# GD32H7xx register map
File version: 1.0
CPU: CM7 r1p2, little endian, MPU, FPU, 4 interrupt priority bits
Registers are 32-bit, read-write, reset 0x0 unless marked. A register's access mark holds for its fields unless they carry their own. Offsets are from the block's base; [hi:lo] are bit positions; {n}, {i} and the like mark numbered series.

## TRNG — True random number generator
Base 0x48021800
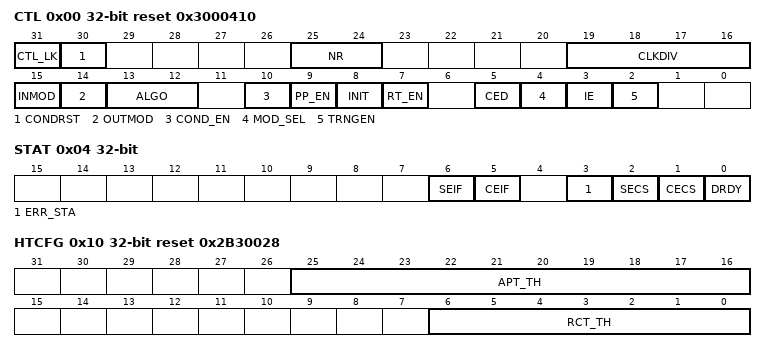
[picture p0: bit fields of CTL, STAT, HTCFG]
0x00 CTL access per field reset 0x3000410 — Control register
  [31] CTL_LK ro — TRNG_CTL register lock bit
  [30] CONDRST rw — reset conditioning logic
  [25:24] NR rw — analog trng power mode
  [19:16] CLKDIV rw — TRNG clock divider
  [15] INMOD rw — select random seed number input to conditioning module
  [14] OUTMOD rw — select random data width output of conditioning module
  [13:12] ALGO rw — None NIST compliant
  [10] COND_EN rw — enable conditioning component
  [9] PP_EN rw — enable post_processing
  [8] INIT rw — init hash algo when conditioning enabled
  [7] RT_EN rw — replace test enable bit
  [5] CED rw — clock error detection
  [4] MOD_SEL rw — LFSR or NIST mode selection
  [3] IE rw — Interrupt enabled bit
  [2] TRNGEN rw — TRNG enabled bit
0x04 STAT access per field — Status register
  [6] SEIF rw — Seed error interrupt flag
  [5] CEIF rw — Clock error interrupt flag
  [3] ERR_STA rw — NIST mode error flag, this bit could be reset by CONDRST
  [2] SECS ro — Seed error current status
  [1] CECS ro — Clock error current status
  [0] DRDY ro — Random data ready status bit
0x08 DATA ro
  [31:0] TRNDATA — 32-bit random data
0x10 HTCFG reset 0x2B30028 — Health tests configure register
  [25:16] APT_TH — Adaptive proportion test threshold
  [6:0] RCT_TH — Repetition count test threshold

## TIMER5 — Basic-timers
Base 0x40001000
Same registers: TIMER6 0x40001400
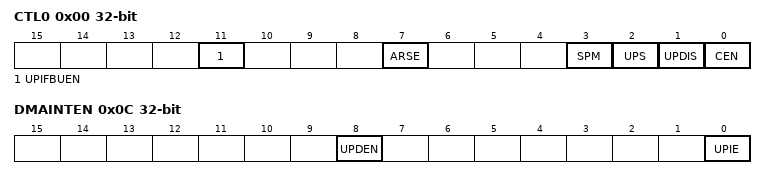
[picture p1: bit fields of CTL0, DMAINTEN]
0x00 CTL0 — control register 0
  [11] UPIFBUEN — UPIF bit backup enable
  [7] ARSE — Auto-reload preload enable
  [3] SPM — One-pulse mode
  [2] UPS — Update request source
  [1] UPDIS — Update disable
  [0] CEN — Counter enable
0x04 CTL1 — control register 1
  [6:4] MMC0 — Master mode selection
0x0C DMAINTEN — DMA/Interrupt enable register
  [8] UPDEN — Update DMA request enable
  [0] UPIE — Update interrupt enable
0x10 INTF — status register
  [0] UPIF — Update interrupt flag
0x14 SWEVG wo — event generation register
  [0] UPG — Update generation
0x24 CNT — counter
  [31:0] CNT — Low counter value
0x28 PSC — prescaler
  [15:0] PSC — Prescaler value
0x2C CARL — Counter auto-reload low register
  [31:0] CARL — Low Auto-reload value

## TIMER50 — Basic-timers
Base 0x4000F000
Same registers: TIMER51 0x4000F400
Registers as TIMER5, without CNT; these are added or differ:
0x24 CNTL — counter
  [31:0] CNTL — Low counter value
0x2C CARL — Counter auto-reload low register
  [31:0] CARLL — Low Auto-reload value
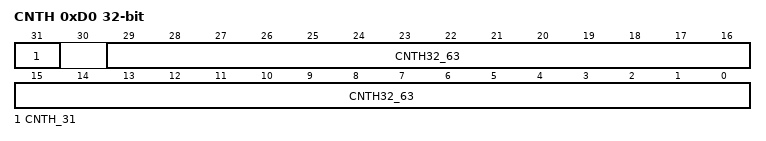
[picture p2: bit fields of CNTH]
0xD0 CNTH — Counter high register
  [31] CNTH_31, [29:0] CNTH32_63
0xD4 CARH — Counter high register
  [31:0] CARLH32_63

## TMU — Trigonometric Math Unit
Base 0x48024400
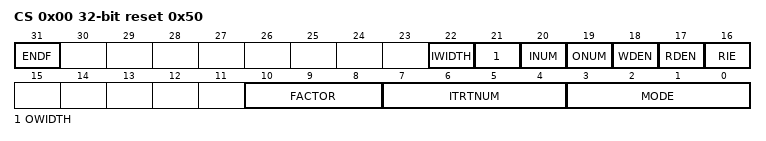
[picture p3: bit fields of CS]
0x00 CS access per field reset 0x50 — Control and status register
  [31] ENDF ro — End of TMU operation flag
  [22] IWIDTH rw — Width of input data
  [21] OWIDTH rw — Width of output data
  [20] INUM rw — The number of times that the IDATA needs to be written
  [19] ONUM rw — The number of times that the ODATA needs to be read
  [18] WDEN rw — Enable DMA request to write IDATA
  [17] RDEN rw — Enable DMA request to read ODATA
  [16] RIE rw — Enable interrupt request to read ODATA
  [10:8] FACTOR rw — Scaling factor
  [7:4] ITRTNUM rw — Number of iterations
  [3:0] MODE rw — Mode of CORDIC operation
0x04 IDATA wo — Input data register
  [31:0] IDATA — The input data
0x08 ODATA ro — Output Data register
  [31:0] ODATA — The output data

## USBHS0_PWRCLK — USB on the go high speed
Base 0x40040E00
Same registers: USBHS1_PWRCLK 0x40080E00
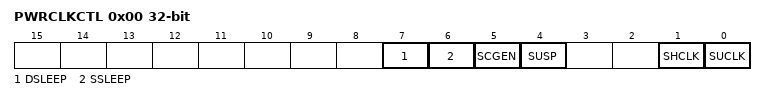
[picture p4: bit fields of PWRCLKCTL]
0x00 PWRCLKCTL access per field — power and clock gating control register (PWRCLKCTL)
  [7] DSLEEP ro — PHY is in deep sleep status
  [6] SSLEEP ro — PHY is in shallow sleep status
  [5] SCGEN ro — internal clock gating enable
  [4] SUSP ro — PHY is in suspend status
  [1] SHCLK rw — Stop HCLK
  [0] SUCLK rw — Stop the USB clock

## VREF
Base 0x58003C00
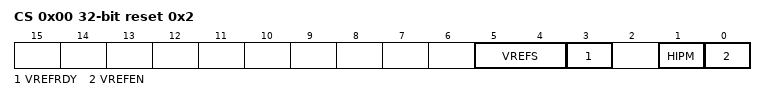
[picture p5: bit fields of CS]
0x00 CS access per field reset 0x2 — Control and status register
  [5:4] VREFS ro — Voltage reference select
  [3] VREFRDY ro — VREF ready
  [1] HIPM rw — High impedance mode
  [0] VREFEN rw — VREF enable
0x04 CALIB — Calibration register
  [5:0] VREFCAL — VREF calibration

## WWDGT — Window watchdog timer
Base 0x50003000
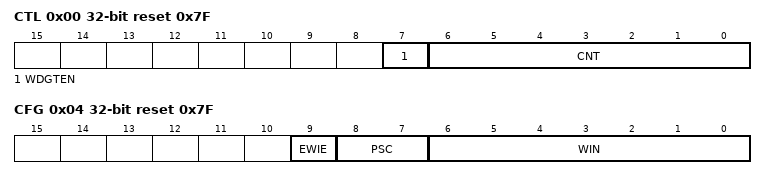
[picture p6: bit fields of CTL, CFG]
0x00 CTL reset 0x7F — Control register
  [7] WDGTEN — Activation bit
  [6:0] CNT — 7-bit counter
0x04 CFG reset 0x7F — Configuration register
  [9] EWIE — Early wakeup interrupt
  [8:7] PSC — Prescaler
  [6:0] WIN — 7-bit window value
0x08 STAT — Status register
  [0] EWIF — Early wakeup interrupt flag

## NVIC — Nested Vectored Interrupt Controller
Base 0xE000E100
{0x0+4i} ISER{i} (i=0..2) — Interrupt Set-Enable Register
  [31:0] SETENA
0x0C ISER3 — Interrupt Set-Enable Register
{0x80+4i} ICER{i} (i=0..2) — Interrupt Clear-Enable Register
  [31:0] CLRENA
0x8C ICER3 — Interrupt Clear-Enable Register
{0x100+4i} ISPR{i} (i=0..2) — Interrupt Set-Pending Register
  [31:0] SETPEND
0x10C ISPR3 — Interrupt Set-Pending Register
{0x180+4i} ICPR{i} (i=0..2) — Interrupt Clear-Pending Register
  [31:0] CLRPEND
0x1C0 ICPR3 — Interrupt Clear-Pending Register
{0x200+4i} IABR{i} ro (i=0..2) — Interrupt Active Bit Register
  [31:0] ACTIVE
0x20C IABR3 — Interrupt Active Bit Register
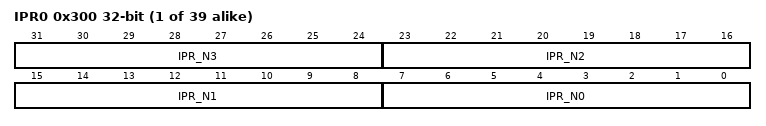
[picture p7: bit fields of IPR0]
{0x300+4i} IPR{i} (i=0..38) — Interrupt Priority Register
  [8n+7:8n] IPR_N{n} (n=0..3)
